# R40 register map
Vendor: Allwinner; Series: R40; File version: 0.1
CPU: CA7 0, little endian, MPU, FPU, double-precision FPU, 0 interrupt priority bits
Registers are 32-bit, read-write, reset 0x0 unless marked. A register's access mark holds for its fields unless they carry their own. Offsets are from the block's base; [hi:lo] are bit positions; 'fields as' and 'values as' point back to an identical list.

## KEYADC
Base 0x01C24400
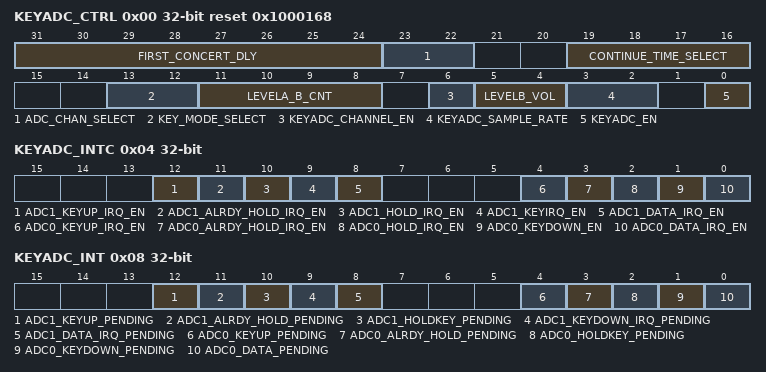
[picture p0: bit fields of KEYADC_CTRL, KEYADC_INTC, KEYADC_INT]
0x00 KEYADC_CTRL reset 0x1000168 — KEYADC Control Register
  [31:24] FIRST_CONCERT_DLY — ADC First Convert Delay Setting. ADC conversion is delayed by n samples
  [23:22] ADC_CHAN_SELECT — ADC channel select 00: ADC0 channel 01: ADC1 channel 1x: ADC0&ADC1 channel
    0=ADC0 (ADC0 channel); 1=ADC1 (ADC1 channel); 2=ADC0_amp_ADC1 (ADC0&ADC1 channel)
  [19:16] CONTINUE_TIME_SELECT — Continue Mode Time Select. Every other 8*(N+1) sample as a valuable sample data.
  [13:12] KEY_MODE_SELECT — Key Mode Select 00: Normal Mode 01: Single Mode 10: Continue Mode
    0=Normal Mode; 1=Single Mode; 2=Continue Mode
  [11:8] LEVELA_B_CNT — Level A to Level B Time Threshold Select. Judge ADC convert value from level A to level B in n+1 samples.
  [6] KEYADC_CHANNEL_EN — KEYADC Channel Enable 0: Disable 1: Enable
    0=Disable; 1=Enable
  [5:4] LEVELB_VOL — Level B Corresponding Data Value Setting (the real voltage value) 00: 0x3C (~1.9V) 01: 0x39 (~1.8V) 10: 0x36 (~1.7V) 11: 0x33 (~1.6V)
    0=0x3C (~1.9V); 1=0x39 (~1.8V); 2=0x36 (~1.7V); 3=0x33 (~1.6V)
  [3:2] KEYADC_SAMPLE_RATE — KEYADC Sample Rate 00: 250Hz 01: 125Hz 10: 62.5Hz 11: 32.25Hz
    0=_250Hz; 1=_125Hz; 2=_62_point_5Hz (62.5Hz); 3=_32_point_25Hz (32.25Hz)
  [0] KEYADC_EN — KEYADC Enable 0: Disable 1: Enable
    0=Disable; 1=Enable
0x04 KEYADC_INTC — KEYADC Interrupt Control Register
  [all] fields
    0=Disable; 1=Enable
  [12] ADC1_KEYUP_IRQ_EN — ADC1 Key Up IRQ Enable 0: Disable 1: Enable
  [11] ADC1_ALRDY_HOLD_IRQ_EN — ADC1 Already Hold Key IRQ Enable 0: Disable 1: Enable
  [10] ADC1_HOLD_IRQ_EN — ADC1 Hold Key IRQ Enable 0: Disable 1: Enable
  [9] ADC1_KEYIRQ_EN — ADC1 Key IRQ Enable 0: Disable 1: Enable
  [8] ADC1_DATA_IRQ_EN — ADC1 DATA IRQ Enable 0: Disable 1: Enable
  [4] ADC0_KEYUP_IRQ_EN — ADC0 Key Up IRQ Enable 0: Disable 1: Enable
  [3] ADC0_ALRDY_HOLD_IRQ_EN — ADC0 Already Hold IRQ Enable 0: Disable 1: Enable
  [2] ADC0_HOLD_IRQ_EN — ADC0 Hold Key IRQ Enable 0: Disable 1: Enable
  [1] ADC0_KEYDOWN_EN — ADC 0 Key Down Enable 0: Disable 1: Enable
  [0] ADC0_DATA_IRQ_EN — ADC 0 Data IRQ Enable 0: Disable 1: Enable
0x08 KEYADC_INT
  [12] ADC1_KEYUP_PENDING write-1-clears — ADC 1 Key up Pending When the General Key pulls up, the corresponding interrupt is enabled. 0: No IRQ 1: IRQ Pending Writing 1 to the bit will clear it and its corresponding interrupt if the interrupt is enabled.
    0=No_IRQ; 1=IRQ (IRQ Pending Writing 1 to the bit will clear it and its corresponding interrupt if the interrupt is enabled.)
  [11] ADC1_ALRDY_HOLD_PENDING write-1-clears — ADC 1 Already Hold Pending When Hold key is in the pull-down state, at this time the general key is pulled down, then is set 1 by hardware if the bit is enabled 0: No IRQ 1: IRQ Pending Writing 1 to the bit will clear it and its corresponding interrupt if the interrupt is enabled
    0=No_IRQ; 1=IRQ (IRQ Pending Writing 1 to the bit will clear it and its corresponding interrupt if the interrupt is enabled)
  [10] ADC1_HOLDKEY_PENDING write-1-clears — ADC 1 Hold Key Pending When the hold key pull down, the status bit is set and the interrupt line is set if the corresponding interrupt bit is enabled. 0: NO IRQ 1: IRQ Pending Writing 1 to the bit will clear it and its corresponding interrupt if the interrupt is enabled.
    0=NO_IRQ; 1=IRQ (IRQ Pending Writing 1 to the bit will clear it and its corresponding interrupt if the interrupt is enabled.)
  [9] ADC1_KEYDOWN_IRQ_PENDING write-1-clears — ADC 1 Key Down IRQ Pending When General key pull down, the status bit is set and the interrupt line is set if the corresponding interrupt is enabled. 0: No IRQ 1: IRQ Pending Writing 1 to the bit will clear it and its corresponding interrupt if the interrupt is enable.
    0=No_IRQ; 1=IRQ (IRQ Pending Writing 1 to the bit will clear it and its corresponding interrupt if the interrupt is enable.)
  [8] ADC1_DATA_IRQ_PENDING write-1-clears — ADC 1 Data IRQ Pending 0: No IRQ 1: IRQ Pending Notes: Writing 1 to the bit will clear it and its corresponding interrupt if the interrupt is enable.
    0=No_IRQ; 1=IRQ (IRQ Pending Notes: Writing 1 to the bit will clear it and its corresponding interrupt if the interrupt is enable.)
  [4] ADC0_KEYUP_PENDING write-1-clears — ADC 0 Key up Pending When general key pull up, the corresponding interrupt is enabled. 0: No IRQ 1: IRQ Pending Notes: Writing 1 to the bit will clear it and its corresponding interrupt if the interrupt is enabled.
    0=No_IRQ; 1=IRQ (IRQ Pending Notes: Writing 1 to the bit will clear it and its corresponding interrupt if the interrupt is enabled.)
  [3] ADC0_ALRDY_HOLD_PENDING write-1-clears — ADC 0 Already Hold Pending When Hold key is in the pull-down state, at this time the general key is pulled down, then is set 1 by hardware if the bit is enabled 0: No IRQ 1: IRQ Pending Writing 1 to the bit will clear it and its corresponding interrupt if the interrupt is enabled.
    values as ADC1_KEYUP_PENDING
  [2] ADC0_HOLDKEY_PENDING write-1-clears — ADC 0 Hold Key Pending When Hold key pull down, the status bit is set and the interrupt line is set if the corresponding interrupt is enabled. 0: NO IRQ 1: IRQ Pending Writing 1 to the bit will clear it and its corresponding interrupt if the interrupt is enabled.
    values as ADC1_HOLDKEY_PENDING
  [1] ADC0_KEYDOWN_PENDING write-1-clears — ADC 0 Key Down IRQ Pending When General key pull down, the status bit is set and the interrupt line is set if the corresponding interrupt is enabled. 0: No IRQ 1: IRQ Pending Writing 1 to the bit will clear it and its corresponding interrupt if the interrupt is enabled.
    values as ADC1_KEYUP_PENDING
  [0] ADC0_DATA_PENDING write-1-clears — ADC 0 Data IRQ Pending 0: No IRQ 1: IRQ Pending Writing 1 to the bit will clear it and its corresponding interrupt if the interrupt is enabled.
    values as ADC1_KEYUP_PENDING
0x0C KEYADC_DATA0 — KEYADC Data Register 0
  [5:0] KEYADC0_DATA ro
0x10 KEYADC_DATA1 — KEYADC Data Register 1
  [5:0] KEYADC1_DATA ro
